# GD32W515 register map
File version: 1.0
CPU: CM33 r0p4, little endian, MPU, FPU, 4 interrupt priority bits
Registers are 32-bit, read-write, reset 0x0 unless marked. A register's access mark holds for its fields unless they carry their own. Offsets are from the block's base; [hi:lo] are bit positions; lines under a group give offsets from that group; {n}, {i} and the like mark numbered series.

## TRNG — Ture random number generator
Base 0x4C060800
Same registers: SEC_TRNG 0x5C060800
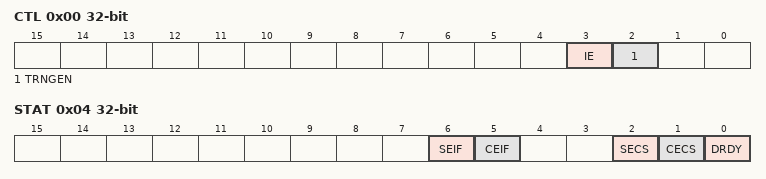
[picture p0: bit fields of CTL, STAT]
0x00 CTL — Control register
  [3] IE — Interrupt bit
  [2] TRNGEN — TRNG enable bit
0x04 STAT access per field — Status register
  [6] SEIF rw — Seed error interrupt flag
  [5] CEIF rw — Clock error interrupt flag
  [2] SECS ro — Seed error current status
  [1] CECS ro — Clock error current status
  [0] DRDY ro — Random data ready status bit
0x08 DATA ro
  [31:0] TRNDATA — 32-bit random data

## TSI — Touch sensing Interface
Base 0x40024000
Same registers: SEC_TSI 0x50024000
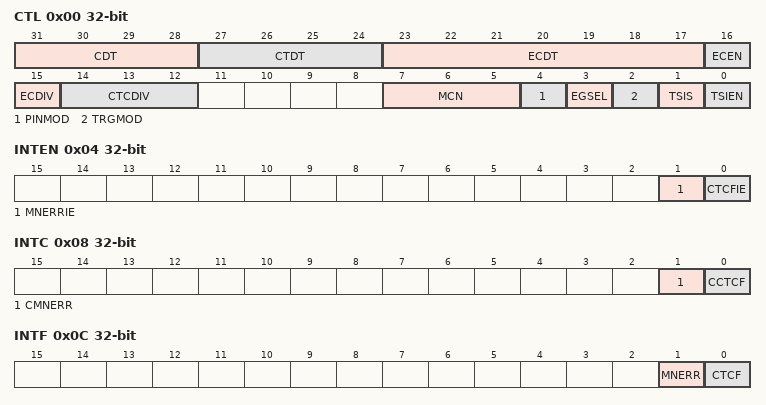
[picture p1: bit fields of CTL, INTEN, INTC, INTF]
0x00 CTL — control register
  [31:28] CDT — Charge transfer pulse high
  [27:24] CTDT — Charge transfer pulse low
  [23:17] ECDT — Spread spectrum deviation
  [16] ECEN — Spread spectrum enable
  [15] ECDIV — Spread spectrum prescaler
  [14:12] CTCDIV — pulse generator prescaler
  [7:5] MCN — Max count value
  [4] PINMOD — I/O Default mode
  [3] EGSEL — Edge selection
  [2] TRGMOD — Trigger mode selection
  [1] TSIS — Start a new acquisition
  [0] TSIEN — Touch sensing controller enable
0x04 INTEN — interrupt enable register
  [1] MNERRIE — Max Cycle Number Error Interrupt Enable
  [0] CTCFIE — Charge-transfer complete flag Interrupt Enable
0x08 INTC wo — interrupt flag clear register
  [1] CMNERR — Clear max cycle number error
  [0] CCTCF — Clear charge-transfer complete flag
0x0C INTF ro — interrupt flag register
  [1] MNERR — Max count error flag
  [0] CTCF — End of acquisition flag
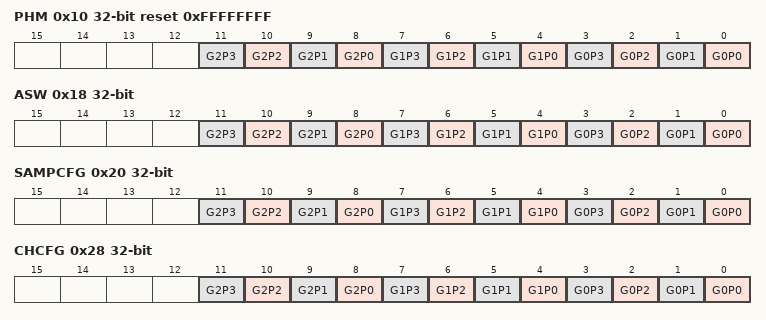
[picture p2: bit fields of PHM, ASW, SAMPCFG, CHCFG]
0x10 PHM reset 0xFFFFFFFF — Pin hysteresis mode register
  [n+8] G2P{n} (n=0..3) — G2P{n} Schmitt trigger hysteresis mode
  [n+4] G1P{n} (n=0..3) — G1P{n} Schmitt trigger hysteresis mode
  [n] G0P{n} (n=0..3) — G0P{n} Schmitt trigger hysteresis mode
0x18 ASW — I/O analog switch register
  [n+8] G2P{n} (n=0..3) — G2P{n} analog switch enable
  [n+4] G1P{n} (n=0..3) — G1P{n} analog switch enable
  [n] G0P{n} (n=0..3) — G0P{n} analog switch enable
0x20 SAMPCFG — I/O sample configuration register
  [n+8] G2P{n} (n=0..3) — G2P{n} sampling mode
  [n+4] G1P{n} (n=0..3) — G1P{n} sampling mode
  [n] G0P{n} (n=0..3) — G0P{n} sampling mode
0x28 CHCFG — I/O channel configuration register
  [n+8] G2P{n} (n=0..3) — G2P{n} channel mode
  [n+4] G1P{n} (n=0..3) — G1P{n} channel mode
  [n] G0P{n} (n=0..3) — G0P{n} channel mode
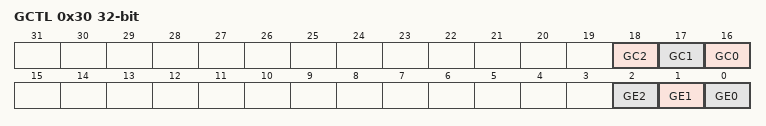
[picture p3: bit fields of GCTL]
0x30 GCTL access per field — I/O group control register
  [18] GC2 ro — Analog I/O group x status
  [17] GC1 ro — Analog I/O group x status
  [16] GC0 ro — Analog I/O group x status
  [2] GE2 rw — Analog I/O group x enable
  [1] GE1 rw — Analog I/O group x enable
  [0] GE0 rw — Analog I/O group x enable
{0x34+4i} G{i}CYCN (i=0..2) — I/O group x cycle number register
  [13:0] CYCN — Cycle number

## TZBMPC0 — Memory protection controller - block based
Base 0x400A0800
Same registers: SEC_TZBMPC0 0x500A0800
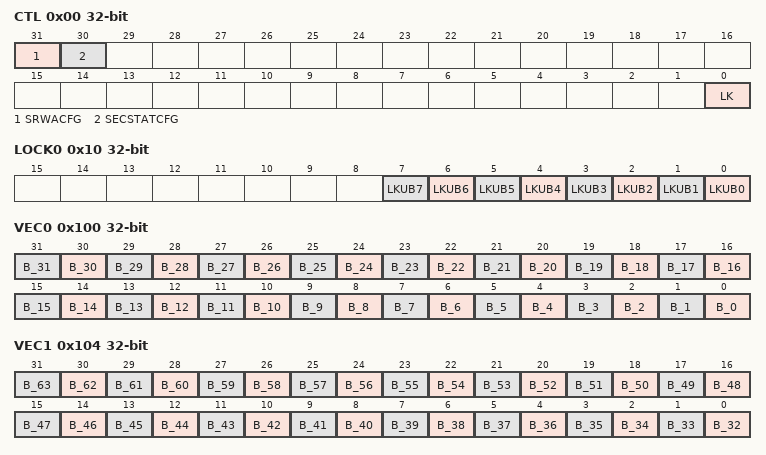
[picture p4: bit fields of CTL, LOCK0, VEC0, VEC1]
0x00 CTL — TZBMPC0 control register
  [31] SRWACFG — secure read/write illegal access disable
  [30] SECSTATCFG — default security state
  [0] LK — TZSPC items lock configuration bit
0x10 LOCK0 — TZBMPC0 lock register 0
  [n] LKUB{n} (n=0..7) — lock/unlock status of secure access mode for the super-blocks {n}
0x100 VEC0 — TZBMPC0 vector register 0
  [n] B_{n} (n=0..31) — blocks {n}
0x104 VEC1 — TZBMPC0 vector register 1
  [n-32] B_{n} (n=32..63) — blocks {n}
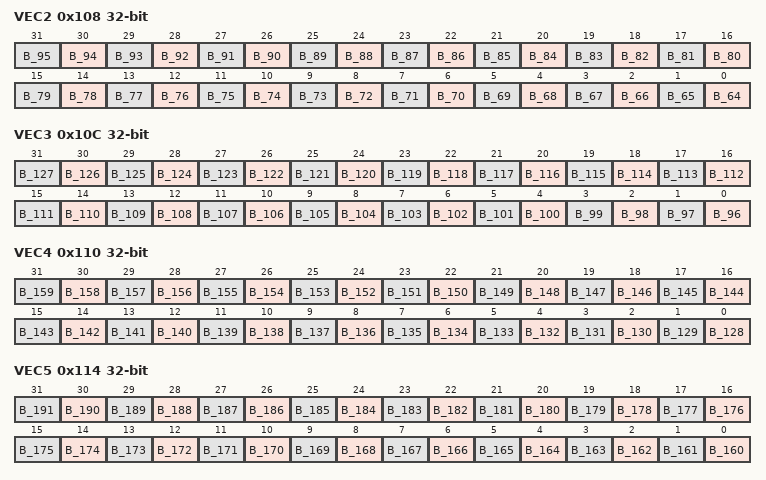
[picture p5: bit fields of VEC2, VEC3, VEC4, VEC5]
0x108 VEC2 — TZBMPC0 vector register 2
  [n-64] B_{n} (n=64..95) — blocks {n}
0x10C VEC3 — TZBMPC0 vector register 3
  [n-96] B_{n} (n=96..127) — blocks {n}
0x110 VEC4 — TZBMPC0 vector register 4
  [n-128] B_{n} (n=128..159) — blocks {n}
0x114 VEC5 — TZBMPC0 vector register 5
  [n-160] B_{n} (n=160..191) — blocks {n}
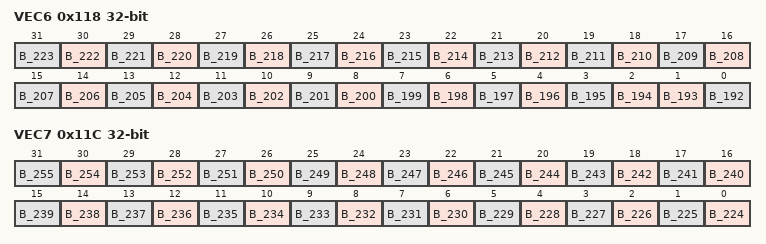
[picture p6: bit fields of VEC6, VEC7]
0x118 VEC6 — TZBMPC0 vector register 6
  [n-192] B_{n} (n=194..223) — blocks {n}
  [1] B_193 — blocks 93
  [0] B_192 — blocks 192
0x11C VEC7 — TZBMPC0 vector register 7
  [n-224] B_{n} (n=224..255) — blocks {n}

## TZBMPC1 — Memory protection controller - block based
Base 0x400A0C00
Same registers: SEC_TZBMPC1 0x500A0C00
Registers as TZBMPC0 (with TZBMPC0 read as TZBMPC1); these are added or differ:
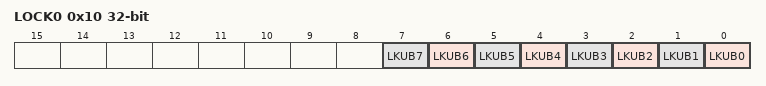
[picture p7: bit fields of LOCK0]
0x10 LOCK0 — TZBMPC1 lock register0
  [n] LKUB{n} (n=0..7) — lock/unlock status of secure access mode for the super-blocks {n}
